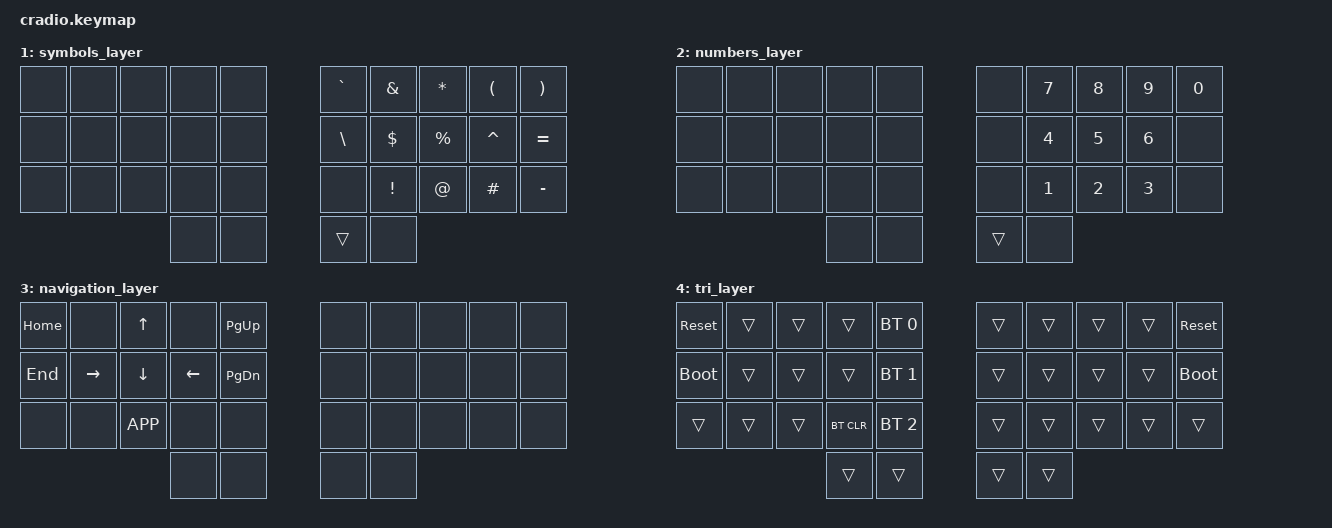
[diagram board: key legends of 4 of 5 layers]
// Copyright (c) 2022 The ZMK Contributors
// SPDX-License-Identifier: MIT

#include <behaviors.dtsi>
#include <dt-bindings/zmk/keys.h>
#include <dt-bindings/zmk/bt.h>

// Home row mods macro
#define HRML(k1,k2,k3,k4) &ht LALT k1  &ht LSHFT k2  &ht LCTRL k3  &ht LGUI k4
#define HRMR(k1,k2,k3,k4) &ht RGUI k1  &ht RCTRL k2  &ht RSHFT k3  &ht RALT k4

/ {
    behaviors {
        ht: hold_tap {
            compatible = "zmk,behavior-hold-tap";
            #binding-cells = <2>;
            flavor = "tap-preferred";
            tapping-term-ms = <220>;
            quick-tap-ms = <150>;
            require-prior-idle-ms = <100>;
            bindings = <&kp>, <&kp>;
        };

        retm: return_m {
            compatible = "zmk,behavior-mod-morph";
            #binding-cells = <0>;
            bindings = <&kp M>, <&kp RETURN>;
            mods = <(MOD_LCTL)>;
        };
        tabi: tab_i {
            compatible = "zmk,behavior-mod-morph";
            #binding-cells = <0>;
            bindings = <&kp I>, <&kp TAB>;
            mods = <(MOD_LCTL)>;
        };
        bspch: backspace_h {
            compatible = "zmk,behavior-mod-morph";
            #binding-cells = <0>;
            bindings = <&kp H>, <&kp BSPC>;
            mods = <(MOD_LCTL)>;
        };
        escsem: escape_semi {
            compatible = "zmk,behavior-mod-morph";
            #binding-cells = <0>;
            bindings = <&kp SEMI>, <&kp ESC>;
            mods = <(MOD_LCTL)>;
        };
    };

    conditional_layers {
        compatible = "zmk,conditional-layers";
        tri_layer {
            if-layers = <1 2>;
            then-layer = <3>;
        };
    };

    combos {
        compatible = "zmk,combos";

        combo_esc {
            timeout-ms = <50>;
            key-positions = <0 1>; // Q + W
            bindings = <&kp ESC>;
        };

        combo_tab {
            timeout-ms = <50>;
            key-positions = <10 11>; // A + S
            bindings = <&kp TAB>;
        };

        combo_enter {
            timeout-ms = <50>;
            key-positions = <18 19>; // L + ;
            bindings = <&kp ENTER>;
        };

        combo_bspc {
            timeout-ms = <50>;
            key-positions = <8 9>; // O + P
            bindings = <&kp BSPC>;
        };

        combo_caps_word {
            timeout-ms = <50>;
            key-positions = <10 19>; // A + ;
            bindings = <&caps_word>; 
        };
    };

    keymap {
        compatible = "zmk,keymap";
        default_layer { // 0
            bindings = <
        //╭──────────┬──────────┬──────────┬──────────┬──────────╮   ╭──────────┬──────────┬──────────┬──────────┬──────────╮
        //│  Q       │  W       │  E       │  R       │  T       │   │  Y       │  U       │  I       │  O       │  P       │
            &kp Q      &kp W      &kp E      &kp R      &kp T          &kp Y      &kp U      &kp I      &kp O      &kp P
        //├──────────┼──────────┼──────────┼──────────┼──────────┤   ├──────────┼──────────┼──────────┼──────────┼──────────┤
        //│  A       │  S       │  D       │  F       │  G       │   │  H       │  J       │  K       │  L       │  ;       │
            &kp A      HRML(S,        D,        F,        G)           HRMR(H,        J,        K,        L)       &escsem
        //├──────────┼──────────┼──────────┼──────────┼──────────┤   ├──────────┼──────────┼──────────┼──────────┼──────────┤
        //│  Z       │  X       │  C       │  V       │  B       │   │  N       │  M       │ , <      │ . >      │ / ?      │
            &kp Z      &kp X      &kp C      &kp V      &kp B          &kp N      &kp M      &kp COMMA  &kp DOT    &kp FSLH
        //╰──────────┴──────────┴──────────┼──────────┼──────────┤   ├──────────┼──────────┼──────────┴──────────┴──────────╯
                                           &lt 2 LBKT  &lt 1 SQT      &lt 3 SPACE &kp RBKT
        //                                 ╰──────────┴──────────╯   ╰──────────┴──────────╯
            >;
        };

        symbols_layer { // 1
            bindings = <
        //╭──────────┬──────────┬──────────┬──────────┬──────────╮   ╭──────────┬──────────┬──────────┬──────────┬──────────╮
        //│          │          │          │          │          │   │  `       │  &       │  *       │  (       │  )       │
            &none      &none      &none      &none      &none          &kp GRAVE  &kp AMPS   &kp ASTRK  &kp LPAR   &kp RPAR
        //├──────────┼──────────┼──────────┼──────────┼──────────┤   ├──────────┼──────────┼──────────┼──────────┼──────────┤
        //│          │          │          │          │          │   │  \       │  $       │  %       │  ^       │  =       │
            &none      &none      &none      &none      &none          &kp BSLH   &kp DLLR   &kp PRCNT  &kp CARET  &kp EQUAL
        //├──────────┼──────────┼──────────┼──────────┼──────────┤   ├──────────┼──────────┼──────────┼──────────┼──────────┤
        //│          │          │          │          │          │   │          │  !       │  @       │  #       │  _       │
            &none      &none      &none      &none      &none          &none      &kp EXCL   &kp AT     &kp HASH   &kp MINUS 
        //╰──────────┴──────────┴──────────┼──────────┼──────────┤   ├──────────┼──────────┼──────────┴──────────┴──────────╯
                                             &none      &none          &trans     &none 
        //                                 ╰──────────┴──────────╯   ╰──────────┴──────────╯
            >;
        };

        numbers_layer { // 2
            bindings = <
        //╭──────────┬──────────┬──────────┬──────────┬──────────╮   ╭──────────┬──────────┬──────────┬──────────┬──────────╮
        //│          │          │          │          │          │   │          │  7       │  8       │  9       │  0       │
            &none      &none      &none      &none      &none          &none      &kp N7     &kp N8     &kp N9     &kp N0   
        //├──────────┼──────────┼──────────┼──────────┼──────────┤   ├──────────┼──────────┼──────────┼──────────┼──────────┤
        //│          │          │          │          │          │   │          │  4       │  5       │  6       │          │
            &none      &none      &none      &none      &none          &none      &kp N4     &kp N5     &kp N6     &none
        //├──────────┼──────────┼──────────┼──────────┼──────────┤   ├──────────┼──────────┼──────────┼──────────┼──────────┤
        //│          │          │          │          │          │   │          │  1       │  2       │  3       │          │
           &none       &none      &none      &none      &none          &none      &kp N1     &kp N2     &kp N3     &none
        //╰──────────┴──────────┴──────────┼──────────┼──────────┤   ├──────────┼──────────┼──────────┴──────────┴──────────╯
                                             &none      &none          &trans     &none 
        //                                 ╰──────────┴──────────╯   ╰──────────┴──────────╯
            >;
        };
        
        navigation_layer { // 3
            bindings = <
        //╭──────────┬──────────┬──────────┬──────────┬──────────╮   ╭──────────┬──────────┬──────────┬──────────┬──────────╮
        //│          │          │          │          │          │   │          │          │          │          │          │
            &kp HOME   &none      &kp UP     &none      &kp PG_UP      &none      &none      &none      &none      &none   
        //├──────────┼──────────┼──────────┼──────────┼──────────┤   ├──────────┼──────────┼──────────┼──────────┼──────────┤
        //│          │          │          │          │          │   │          │          │          │          │          │
            &kp END    &kp RIGHT  &kp DOWN   &kp LEFT   &kp PG_DN      &none      &none      &none      &none      &none
        //├──────────┼──────────┼──────────┼──────────┼──────────┤   ├──────────┼──────────┼──────────┼──────────┼──────────┤
        //│          │          │          │          │          │   │          │          │          │          │          │
            &none      &none      &kp K_APP  &none      &none          &none      &none      &none      &none      &none
        //╰──────────┴──────────┴──────────┼──────────┼──────────┤   ├──────────┼──────────┼──────────┴──────────┴──────────╯
                                             &none      &none          &none     &none
        //                                 ╰──────────┴──────────╯   ╰──────────┴──────────╯
            >;
        };



        tri_layer {
            bindings = <
        //╭──────────┬──────────┬──────────┬──────────┬──────────╮   ╭──────────┬──────────┬──────────┬──────────┬──────────╮
        //│ RESET    │          │          │          │PROFILE 0 │   │          │          │          │          │  RESET   │
           &sys_reset  &trans     &trans     &trans    &bt BT_SEL 0    &trans     &trans     &trans     &trans    &sys_reset
        //├──────────┼──────────┼──────────┼──────────┼──────────┤   ├──────────┼──────────┼──────────┼──────────┼──────────┤
        //│BOOTLOADER│          │          │          │PROFILE 1 │   │          │          │          │          │BOOTLOADER│
          &bootloader  &trans     &trans     &trans    &bt BT_SEL 1    &trans     &trans     &trans     &trans    &bootloader
        //├──────────┼──────────┼──────────┼──────────┼──────────┤   ├──────────┼──────────┼──────────┼──────────┼──────────┤
        //│          │          │          │ CLEAR BT │PROFILE 2 │   │          │          │          │          │          │
            &trans     &trans     &trans    &bt BT_CLR &bt BT_SEL 2    &trans     &trans     &trans     &trans     &trans
        //╰──────────┴──────────┴──────────┼──────────┼──────────┤   ├──────────┼──────────┼──────────┴──────────┴──────────╯
                                             &trans     &trans         &trans     &trans
        //                                 ╰──────────┴──────────╯   ╰──────────┴──────────╯
            >;
        };
    };
};
